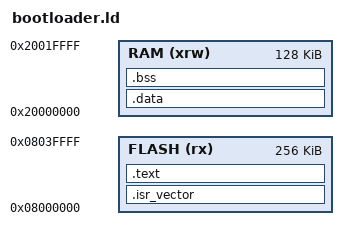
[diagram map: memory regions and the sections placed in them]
/* Minimal linker script for a small bootloader on STM32
   Bootloader: 0x08000000 - 0x08003FFF (16KB)
   Application: 0x08004000 - end
*/

ENTRY(Reset_Handler)

MEMORY
{
  FLASH (rx) : ORIGIN = 0x08000000, LENGTH = 256K
  RAM (xrw)  : ORIGIN = 0x20000000, LENGTH = 128K
}

SECTIONS
{
  .isr_vector :
  {
    KEEP(*(.isr_vector))
  } > FLASH

  .text :
  {
    *(.text*)
    *(.rodata*)
    _etext = .;
  } > FLASH

  .data : AT ( _etext )
  {
    _sdata = .;
    *(.data*)
    _edata = .;
  } > RAM

  .bss :
  {
    _sbss = .;
    *(.bss*)
    *(COMMON)
    _ebss = .;
  } > RAM

  /DISCARD/ : { *(.comment) }
}
